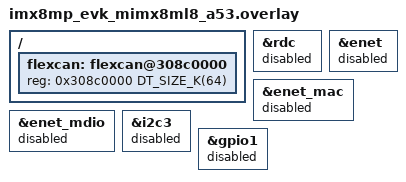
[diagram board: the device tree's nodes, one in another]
/*
 * Copyright 2023-2025 NXP
 *
 * SPDX-License-Identifier: BSD-3-Clause
 */

#include "gpt.dtsi"

/ {
	flexcan: flexcan@308c0000 {
		reg = <0x308c0000 DT_SIZE_K(64)>;
	};
};

&rdc {
	status = "disabled";
};

&enet {
	status = "disabled";
};

&enet_mac {
	status = "disabled";
};

&enet_mdio {
	status = "disabled";
};

&i2c3 {
	status = "disabled";
};

&gpio1 {
	status = "disabled";
};
